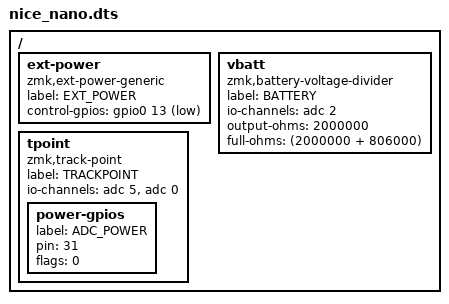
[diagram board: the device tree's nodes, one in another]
/*
 * Copyright (c) 2021 The ZMK Contributors
 *
 * SPDX-License-Identifier: MIT
 */

/dts-v1/;
#include "nice_nano.dtsi"

/ {
	ext-power {
		compatible = "zmk,ext-power-generic";
		label = "EXT_POWER";
		control-gpios = <&gpio0 13 GPIO_ACTIVE_LOW>;
	};

	vbatt {
		compatible = "zmk,battery-voltage-divider";
		label = "BATTERY";
		io-channels = <&adc 2>;
		output-ohms = <2000000>;
		full-ohms = <(2000000 + 806000)>;
	};
	tpoint {
		compatible = "zmk,track-point";
		label = "TRACKPOINT";
		io-channels = <&adc 5>,<&adc 0>;
		power-gpios {
		    label = "ADC_POWER";
		    pin = <31>;
		    flags = <0>;
		    };
	};
};
